AUTOSAR XML (schema 4-0-3)
standard types defined: uint8, Boolean, UInt16, UInt32, UInt8
package /AUTOSAR_Platform/DataConstrs
  range DC_Boolean: raw 0..1
  range DC_UInt16: raw 0..65535
  range DC_UInt8: raw 0..255
package /PATAC/Facility/DataTypes/Implementation
  compu method COMPU_Boolean: 0=FALSE, 1=TRUE
  unit NoUnit: factor-si-to-unit=1, offset-si-to-unit=0
package /PATAC/MSM/ComponentTypes
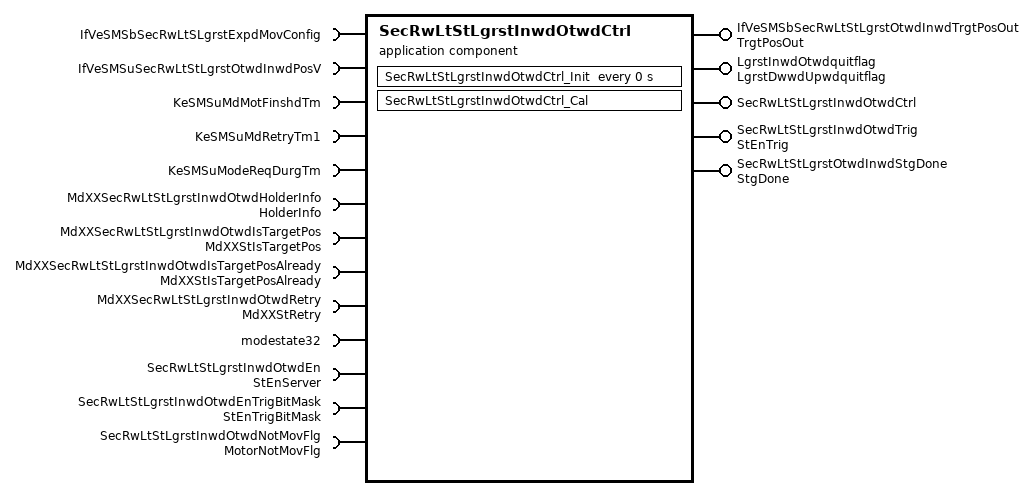
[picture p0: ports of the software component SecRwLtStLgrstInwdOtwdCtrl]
  application sw component type SecRwLtStLgrstInwdOtwdCtrl
    5 x provide port:
      IfVeSMSbSecRwLtStLgrstOtwdInwdTrgtPosOut: nonqueued-sender-com-spec{data-element=TrgtPosOut/Val, init-value=0}, provided-interface=TrgtPosOut
      LgrstInwdOtwdquitflag: nonqueued-sender-com-spec{data-element=LgrstDwwdUpwdquitflag/Val, init-value=0}, provided-interface=LgrstDwwdUpwdquitflag
      SecRwLtStLgrstInwdOtwdCtrl: server-com-spec{operation=Cal, queue-length=1}, provided-interface=SecRwLtStLgrstInwdOtwdCtrl
      SecRwLtStLgrstInwdOtwdTrig: nonqueued-sender-com-spec{data-element=StEnTrig/Val, init-value=0}, provided-interface=StEnTrig
      SecRwLtStLgrstOtwdInwdStgDone: nonqueued-sender-com-spec{data-element=StgDone/Val, init-value=0}, provided-interface=StgDone
    13 x require port:
      IfVeSMSbSecRwLtSLgrstExpdMovConfig: nonqueued-receiver-com-spec{data-element=IfVeSMSbSecRwLtSLgrstExpdMovConfig/Val, filter=data-filter-type=ALWAYS, init-value=1}, required-interface=IfVeSMSbSecRwLtSLgrstExpdMovConfig
      IfVeSMSuSecRwLtStLgrstOtwdInwdPosV: nonqueued-receiver-com-spec{data-element=IfVeSMSuSecRwLtStLgrstOtwdInwdPosV/Val, filter=data-filter-type=ALWAYS, init-value=0}, required-interface=IfVeSMSuSecRwLtStLgrstOtwdInwdPosV
      KeSMSuMdMotFinshdTm: parameter-require-com-spec{init-value=0, parameter=KeSMSuMdMotFinshdTm/Val}, required-interface=KeSMSuMdMotFinshdTm
      KeSMSuMdRetryTm1: parameter-require-com-spec{init-value=0, parameter=KeSMSuMdRetryTm1/Val}, required-interface=KeSMSuMdRetryTm1
      KeSMSuModeReqDurgTm: parameter-require-com-spec{init-value=0, parameter=KeSMSuModeReqDurgTm/Val}, required-interface=KeSMSuModeReqDurgTm
      MdXXSecRwLtStLgrstInwdOtwdHolderInfo: nonqueued-receiver-com-spec{data-element=HolderInfo/Val, filter=data-filter-type=ALWAYS, init-value=0}, required-interface=HolderInfo
      MdXXSecRwLtStLgrstInwdOtwdIsTargetPos: nonqueued-receiver-com-spec{data-element=MdXXStIsTargetPos/Val, filter=data-filter-type=ALWAYS, init-value=0}, required-interface=MdXXStIsTargetPos
      MdXXSecRwLtStLgrstInwdOtwdIsTargetPosAlready: nonqueued-receiver-com-spec{data-element=MdXXStIsTargetPosAlready/Val, filter=data-filter-type=ALWAYS, init-value=0}, required-interface=MdXXStIsTargetPosAlready
      MdXXSecRwLtStLgrstInwdOtwdRetry: nonqueued-receiver-com-spec{data-element=MdXXStRetry/Val, filter=data-filter-type=ALWAYS, init-value=0}, required-interface=MdXXStRetry
      modestate32: nonqueued-receiver-com-spec{data-element=modestate32/Val, filter=data-filter-type=ALWAYS, init-value=0}, required-interface=modestate32
      SecRwLtStLgrstInwdOtwdEn: required-com-specs=[Clear, Get, Set], required-interface=StEnServer
      SecRwLtStLgrstInwdOtwdEnTrigBitMask: nonqueued-receiver-com-spec{data-element=StEnTrigBitMask/Val, filter=data-filter-type=ALWAYS, init-value=0}, required-interface=StEnTrigBitMask
      SecRwLtStLgrstInwdOtwdNotMovFlg: nonqueued-receiver-com-spec{data-element=MotorNotMovFlg/Val, filter=data-filter-type=ALWAYS, init-value=0}, required-interface=MotorNotMovFlg
    behavior SecRwLtStLgrstInwdOtwdCtrl_InternalBehavior
      operation invoked event OIT_SecRwLtStLgrstInwdOtwdCtrl_Cal_SecRwLtStLgrstInwdOtwdCtrl_Cal: start-on-event=SecRwLtStLgrstInwdOtwdCtrl_Cal, operation=SecRwLtStLgrstInwdOtwdCtrl.Cal
      timing event SecRwLtStLgrstInwdOtwdCtrl_InitEvent: start-on-event=SecRwLtStLgrstInwdOtwdCtrl_Init, period=0
      runnable SecRwLtStLgrstInwdOtwdCtrl_Cal
        data-receive-point-by-arguments:
          9 x access:
            REC_IfVeSMSbSecRwLtSLgrstExpdMovConfig_Val: accessed-variable=IfVeSMSbSecRwLtSLgrstExpdMovConfig.Val
            REC_IfVeSMSuSecRwLtStLgrstOtwdInwdPosV_Val: accessed-variable=IfVeSMSuSecRwLtStLgrstOtwdInwdPosV.Val
            REC_MdXXSecRwLtStLgrstInwdOtwdHolderInfo_Val: accessed-variable=MdXXSecRwLtStLgrstInwdOtwdHolderInfo.Val
            REC_MdXXSecRwLtStLgrstInwdOtwdIsTargetPos_Val: accessed-variable=MdXXSecRwLtStLgrstInwdOtwdIsTargetPos.Val
            REC_MdXXSecRwLtStLgrstInwdOtwdIsTargetPosAlready_Val: accessed-variable=MdXXSecRwLtStLgrstInwdOtwdIsTargetPosAlready.Val
            REC_MdXXSecRwLtStLgrstInwdOtwdRetry_Val: accessed-variable=MdXXSecRwLtStLgrstInwdOtwdRetry.Val
            REC_modestate32_Val: accessed-variable=modestate32.Val
            REC_SecRwLtStLgrstInwdOtwdEnTrigBitMask_Val: accessed-variable=SecRwLtStLgrstInwdOtwdEnTrigBitMask.Val
            REC_SecRwLtStLgrstInwdOtwdNotMovFlg_Val: accessed-variable=SecRwLtStLgrstInwdOtwdNotMovFlg.Val
        data-send-points:
          4 x access:
            SEND_IfVeSMSbSecRwLtStLgrstOtwdInwdTrgtPosOut_Val: accessed-variable=IfVeSMSbSecRwLtStLgrstOtwdInwdTrgtPosOut.Val
            SEND_LgrstInwdOtwdquitflag_Val: accessed-variable=LgrstInwdOtwdquitflag.Val
            SEND_SecRwLtStLgrstInwdOtwdTrig_Val: accessed-variable=SecRwLtStLgrstInwdOtwdTrig.Val
            SEND_SecRwLtStLgrstOtwdInwdStgDone_Val: accessed-variable=SecRwLtStLgrstOtwdInwdStgDone.Val
        parameter access PA_KeSMSuMdMotFinshdTm_Val: accessed-parameter=KeSMSuMdMotFinshdTm.Val
        parameter access PA_KeSMSuMdRetryTm1_Val: accessed-parameter=KeSMSuMdRetryTm1.Val
        parameter access PA_KeSMSuModeReqDurgTm_Val: accessed-parameter=KeSMSuModeReqDurgTm.Val
        sync call SC_SecRwLtStLgrstInwdOtwdEn_Get: operation=SecRwLtStLgrstInwdOtwdEn.Get, timeout=0
      runnable SecRwLtStLgrstInwdOtwdCtrl_Init
        parameter access PA_KeSMSuMdMotFinshdTm_Val: accessed-parameter=KeSMSuMdMotFinshdTm.Val
        parameter access PA_KeSMSuMdRetryTm1_Val: accessed-parameter=KeSMSuMdRetryTm1.Val
        parameter access PA_KeSMSuModeReqDurgTm_Val: accessed-parameter=KeSMSuModeReqDurgTm.Val
  swc implementation SecRwLtStLgrstInwdOtwdCtrl_Implementation: behavior=SecRwLtStLgrstInwdOtwdCtrl_InternalBehavior
    code-descriptors:
      code Default: artifact-descriptors=autosar-engineering-object={short-label=Default, category=SWSRC}
package /PATAC/MSM/ModeAdjust/CalPortInterface
  parameter interface KeSMSuMdMotFinshdTm
    parameter data prototype Val: sw-calibration-access=READ-WRITE, type=UInt16
  parameter interface KeSMSuModeReqDurgTm
    parameter data prototype Val: sw-calibration-access=READ-WRITE, type=UInt16
package /PATAC/MSM/ModeAdjust/PortInterface
  client server interface SecRwLtStLgrstInwdOtwdCtrl
    operation Cal
  client server interface StEnServer
    operation Clear
      arg data: type=UInt8, direction=IN, server-argument-impl-policy=USE-ARGUMENT-TYPE
    operation Get
      arg data: type=UInt32, direction=OUT, server-argument-impl-policy=USE-ARGUMENT-TYPE
    operation Set
      arg data: type=UInt8, direction=IN, server-argument-impl-policy=USE-ARGUMENT-TYPE
  11 x sender receiver interface:
    HolderInfo: invalidation-policy{data-element=HolderInfo/Val, handle-invalid=DONT-INVALIDATE}
      data Val: type=UInt32
    LgrstDwwdUpwdquitflag: invalidation-policy{data-element=LgrstDwwdUpwdquitflag/Val, handle-invalid=DONT-INVALIDATE}
      data Val: type=Boolean
    MdXXStIsTargetPos: invalidation-policy{data-element=MdXXStIsTargetPos/Val, handle-invalid=DONT-INVALIDATE}
      data Val: type=UInt32
    MdXXStIsTargetPosAlready: invalidation-policy{data-element=MdXXStIsTargetPosAlready/Val, handle-invalid=DONT-INVALIDATE}
      data Val: type=UInt32
    MdXXStRetry: invalidation-policy{data-element=MdXXStRetry/Val, handle-invalid=DONT-INVALIDATE}
      data Val: type=UInt32
    modestate32: invalidation-policy{data-element=modestate32/Val, handle-invalid=DONT-INVALIDATE}
      data Val: type=UInt32
    MotorNotMovFlg: invalidation-policy{data-element=MotorNotMovFlg/Val, handle-invalid=DONT-INVALIDATE}
      data Val: type=Boolean
    StEnTrig: invalidation-policy{data-element=StEnTrig/Val, handle-invalid=DONT-INVALIDATE}
      data Val: type=Boolean
    StEnTrigBitMask: invalidation-policy{data-element=StEnTrigBitMask/Val, handle-invalid=DONT-INVALIDATE}
      data Val: type=UInt32
    StgDone: invalidation-policy{data-element=StgDone/Val, handle-invalid=DONT-INVALIDATE}
      data Val: type=Boolean
    TrgtPosOut: invalidation-policy{data-element=TrgtPosOut/Val, handle-invalid=DONT-INVALIDATE}
      data Val: type=Boolean
package /PATAC/MSM/PortInterfaces
  parameter interface KeSMSuMdRetryTm1
    parameter data prototype Val: sw-calibration-access=READ-WRITE, type=UInt8
  sender receiver interface IfVeSMSbSecRwLtSLgrstExpdMovConfig: invalidation-policy{data-element=IfVeSMSbSecRwLtSLgrstExpdMovConfig/Val, handle-invalid=DONT-INVALIDATE}
    data Val: type=Boolean
  sender receiver interface IfVeSMSuSecRwLtStLgrstOtwdInwdPosV: invalidation-policy{data-element=IfVeSMSuSecRwLtStLgrstOtwdInwdPosV/Val, handle-invalid=DONT-INVALIDATE}
    data Val: type=Boolean
